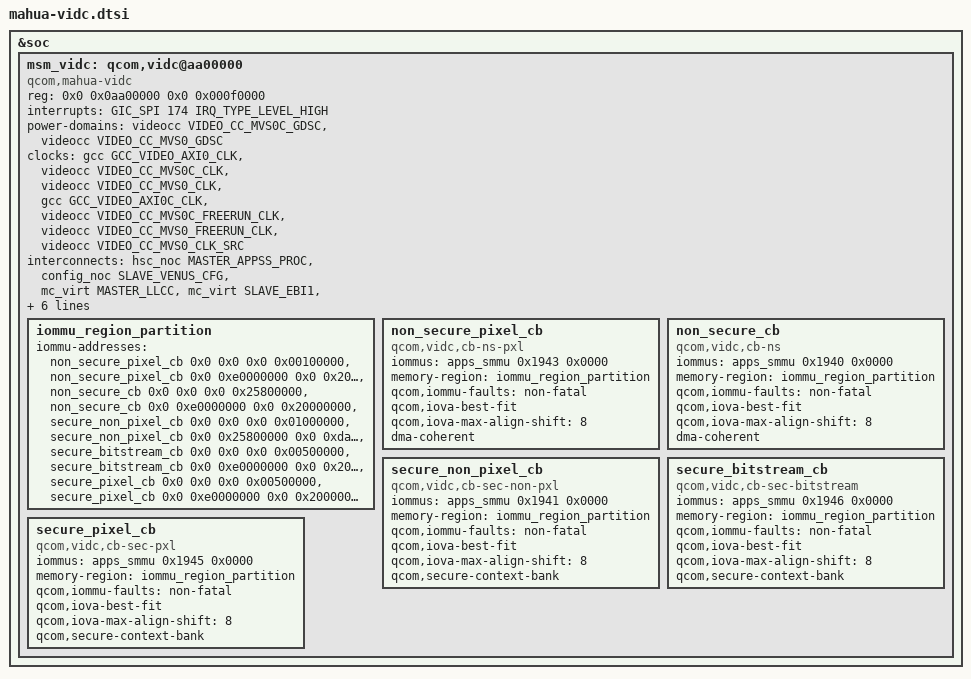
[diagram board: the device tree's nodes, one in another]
// SPDX-License-Identifier: BSD-3-Clause
/*
 * Copyright (c) Qualcomm Technologies, Inc. and/or its subsidiaries.
 */

&soc {
	msm_vidc: qcom,vidc@aa00000 {
		compatible = "qcom,mahua-vidc";
		status = "okay";

		/* IOMMU Config */
		#address-cells = <2>;
		#size-cells = <2>;
		reg = <0x0 0x0aa00000 0x0 0x000f0000>;
		interrupts = <GIC_SPI 174 IRQ_TYPE_LEVEL_HIGH>;

		/* Power Domains */
		power-domains = <&videocc VIDEO_CC_MVS0C_GDSC>,
				<&videocc VIDEO_CC_MVS0_GDSC>;
		power-domain-names = "venus", "vcodec0";

		/* Clocks */

		clocks = <&gcc GCC_VIDEO_AXI0_CLK>,
			 <&videocc VIDEO_CC_MVS0C_CLK>,
			 <&videocc VIDEO_CC_MVS0_CLK>,
			 <&gcc GCC_VIDEO_AXI0C_CLK>,
			 <&videocc VIDEO_CC_MVS0C_FREERUN_CLK>,
			 <&videocc VIDEO_CC_MVS0_FREERUN_CLK>,
			 <&videocc VIDEO_CC_MVS0_CLK_SRC>;

		clock-names = "iface",
			      "core",
			      "vcodec0_core",
			      "iface1",
			      "core_freerun",
			      "vcodec0_core_freerun",
			      "video_cc_mvs0_clk_src";

		interconnects = <&hsc_noc MASTER_APPSS_PROC &config_noc SLAVE_VENUS_CFG>,
                                <&mc_virt MASTER_LLCC &mc_virt SLAVE_EBI1>,
                                <&mmss_noc MASTER_VIDEO &hsc_noc SLAVE_LLCC>;

		interconnect-names = "cpu-cfg",
				     "video-mem",
                                     "venus-llcc";

		/* FW load region */
		memory-region = <&video_mem>;

				/* Clock Resets */
		resets = <&gcc GCC_VIDEO_AXI0_CLK_ARES>,
			 <&gcc GCC_VIDEO_AXI0C_CLK_ARES>,
			 <&videocc VIDEO_CC_MVS0C_FREERUN_CLK_ARES>,
			 <&videocc VIDEO_CC_MVS0_FREERUN_CLK_ARES>;

		reset-names ="bus0",
			     "bus1",
			     "core",
			     "vcodec0_core";
		/* MMUs */
		iommu_region_partition: iommu_region_partition {
			/* These IOVA regions are unique per context bank */
			iommu-addresses =
				<&non_secure_pixel_cb 0x0 0x0 0x0 0x00100000>,
				<&non_secure_pixel_cb 0x0 0xe0000000 0x0 0x20000000>,
				<&non_secure_cb 0x0 0x0 0x0 0x25800000>,
				<&non_secure_cb 0x0 0xe0000000 0x0 0x20000000>,
				<&secure_non_pixel_cb 0x0 0x0 0x0 0x01000000>,
				<&secure_non_pixel_cb 0x0 0x25800000 0x0 0xda800000>,
				<&secure_bitstream_cb 0x0 0x0 0x0 0x00500000>,
				<&secure_bitstream_cb 0x0 0xe0000000 0x0 0x20000000>,
				<&secure_pixel_cb 0x0 0x0 0x0 0x00500000>,
				<&secure_pixel_cb 0x0 0xe0000000 0x0 0x20000000>;
		};

		non_secure_pixel_cb: non_secure_pixel_cb {
			compatible = "qcom,vidc,cb-ns-pxl";
			iommus = <&apps_smmu 0x1943 0x0000>;
			memory-region = <&iommu_region_partition>;
			qcom,iommu-faults = "non-fatal";
			qcom,iova-best-fit;
			/* log2 of desired alignment (1MB) - log2 of PAGE_SIZE; (8 = 20 - 12) */
			qcom,iova-max-align-shift = <8>;
			dma-coherent;
		};

		non_secure_cb: non_secure_cb {
			compatible = "qcom,vidc,cb-ns";
			iommus = <&apps_smmu 0x1940 0x0000>;
			memory-region = <&iommu_region_partition>;
			qcom,iommu-faults = "non-fatal";
			qcom,iova-best-fit;
			qcom,iova-max-align-shift = <8>; /* 1 MB */
			dma-coherent;
		};

		secure_non_pixel_cb: secure_non_pixel_cb {
			compatible = "qcom,vidc,cb-sec-non-pxl";
			iommus = <&apps_smmu 0x1941 0x0000>;
			memory-region = <&iommu_region_partition>;
			qcom,iommu-faults = "non-fatal";
			qcom,iova-best-fit;
			qcom,iova-max-align-shift = <8>; /* 1 MB */
			qcom,secure-context-bank;
		};

		secure_bitstream_cb: secure_bitstream_cb {
			compatible = "qcom,vidc,cb-sec-bitstream";
			iommus = <&apps_smmu 0x1946 0x0000>;
			memory-region = <&iommu_region_partition>;
			qcom,iommu-faults = "non-fatal";
			qcom,iova-best-fit;
			qcom,iova-max-align-shift = <8>; /* 1 MB */
			qcom,secure-context-bank;
		};

		secure_pixel_cb: secure_pixel_cb {
			compatible = "qcom,vidc,cb-sec-pxl";
			iommus = <&apps_smmu 0x1945 0x0000>;
			memory-region = <&iommu_region_partition>;
			qcom,iommu-faults = "non-fatal";
			qcom,iova-best-fit;
			qcom,iova-max-align-shift = <8>; /* 1 MB */
			qcom,secure-context-bank;
		};
	};
};
